VERSION ""

CM_ "Comma Pedal (Tesla Pre-AP gas interceptor) for BogPilot nap-pedal.
Copied unchanged from BogGyver/Tinkla openpilot 0d99a1b, opendbc/tesla_can.dbc
messages 1361 GAS_COMMAND and 1362 GAS_SENSOR (MIT), which match the Tinkla pedal
firmware panda/board/pedal/main.c (CAN_GAS_INPUT 0x551, CAN_GAS_OUTPUT 0x552,
sensor byte 4 = (state << 4) | idx). NotAutopilot opendbc cc39c7f and napdbc
f1a756d tesla_preap.dbc list GAS_SENSOR STATE at 35|4 and IDX at 39|4, the
reverse of the firmware; this file follows the firmware. CHECKSUM is the
additive pedal checksum (address bytes + data bytes 0-4), computed by hand in
selfdrive/car/tesla/preap_pedal.py; the signals are deliberately not named
CHECKSUM_PEDAL / COUNTER_PEDAL so opendbc does not apply comma's CRC pedal check.
Kept separate so opendbc/tesla_can.dbc is unchanged.";

NS_ :

BS_:

BU_: EON INTERCEPTOR

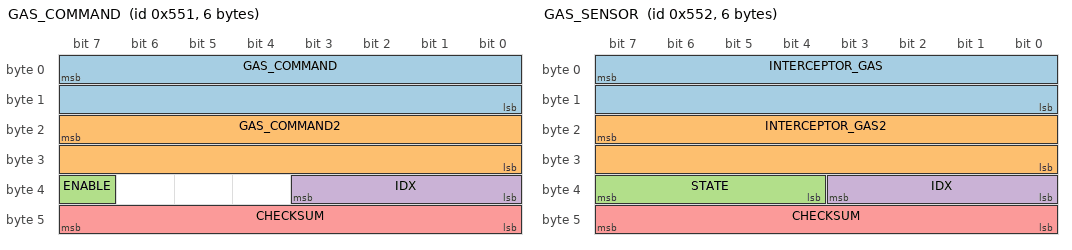
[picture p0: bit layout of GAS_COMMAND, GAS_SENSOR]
BO_ 1361 GAS_COMMAND: 6 EON
 SG_ GAS_COMMAND : 7|16@0+ (0.0507968128,-22.85856576) [0|1] "" INTERCEPTOR
 SG_ GAS_COMMAND2 : 23|16@0+ (0.1015936256,-22.85856576) [0|1] "" INTERCEPTOR
 SG_ ENABLE : 39|1@0+ (1,0) [0|1] "" INTERCEPTOR
 SG_ IDX : 35|4@0+ (1,0) [0|15] "" INTERCEPTOR
 SG_ CHECKSUM : 47|8@0+ (1,0) [0|255] "" INTERCEPTOR

BO_ 1362 GAS_SENSOR: 6 INTERCEPTOR
 SG_ INTERCEPTOR_GAS : 7|16@0+ (0.0507968128,-22.85856576) [0|1] "" EON
 SG_ INTERCEPTOR_GAS2 : 23|16@0+ (0.1015936256,-22.85856576) [0|1] "" EON
 SG_ STATE : 39|4@0+ (1,0) [0|15] "" EON
 SG_ IDX : 35|4@0+ (1,0) [0|15] "" EON
 SG_ CHECKSUM : 47|8@0+ (1,0) [0|255] "" EON

VAL_ 1362 STATE 6 "FAULT_INVALID" 5 "FAULT_TIMEOUT" 4 "FAULT_STARTUP" 3 "FAULT_SCE" 2 "FAULT_SEND" 1 "FAULT_BAD_CHECKSUM" 0 "NO_FAULT" ;
